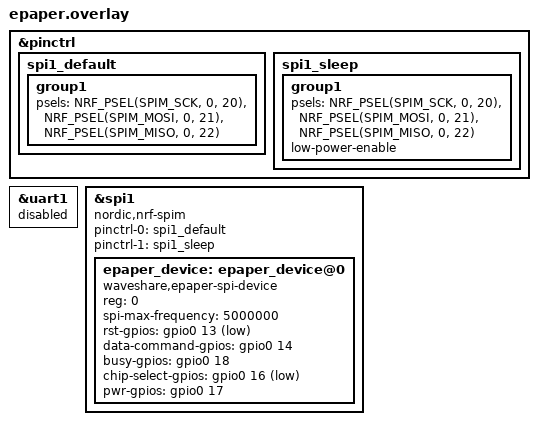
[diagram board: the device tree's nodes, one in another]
&pinctrl {
    spi1_default: spi1_default {
		group1 {
			psels = <NRF_PSEL(SPIM_SCK, 0, 20)>,
			        <NRF_PSEL(SPIM_MOSI, 0, 21)>,
			        <NRF_PSEL(SPIM_MISO, 0, 22)>;
		};
	};

	spi1_sleep: spi1_sleep {
		group1 {
			psels = <NRF_PSEL(SPIM_SCK, 0, 20)>,
			        <NRF_PSEL(SPIM_MOSI, 0, 21)>,
			        <NRF_PSEL(SPIM_MISO, 0, 22)>;
			low-power-enable;
		};
	};
};

&uart1 {
    status = "disabled";
};

&spi1 {
    compatible = "nordic,nrf-spim";
    status = "okay";
	//cs-gpios  = <&gpio0 16 GPIO_ACTIVE_LOW>;
	pinctrl-0 = <&spi1_default>;
    pinctrl-1 = <&spi1_sleep>;
    pinctrl-names = "default", "sleep";
    epaper_device: epaper_device@0 {
        compatible = "waveshare,epaper-spi-device";
        reg = <0>;
		// Write speed can go up to 20MHz, but Read speed is only up to 2.5MHz. 
		// But the device does not have a MOSI pin connection, so always only "write" to it.
		spi-max-frequency = <5000000>;	// Conservative 5MHz

        // --- Additional GPIOs defined here ---
        rst-gpios   = <&gpio0 13 GPIO_ACTIVE_LOW>;
        data-command-gpios    = <&gpio0 14 GPIO_ACTIVE_HIGH>;
        busy-gpios  = <&gpio0 18 (GPIO_PULL_DOWN | GPIO_ACTIVE_HIGH)>; // Input
		chip-select-gpios  = <&gpio0 16 GPIO_ACTIVE_LOW>;
        pwr-gpios = <&gpio0 17 GPIO_ACTIVE_HIGH>;
    };
};

